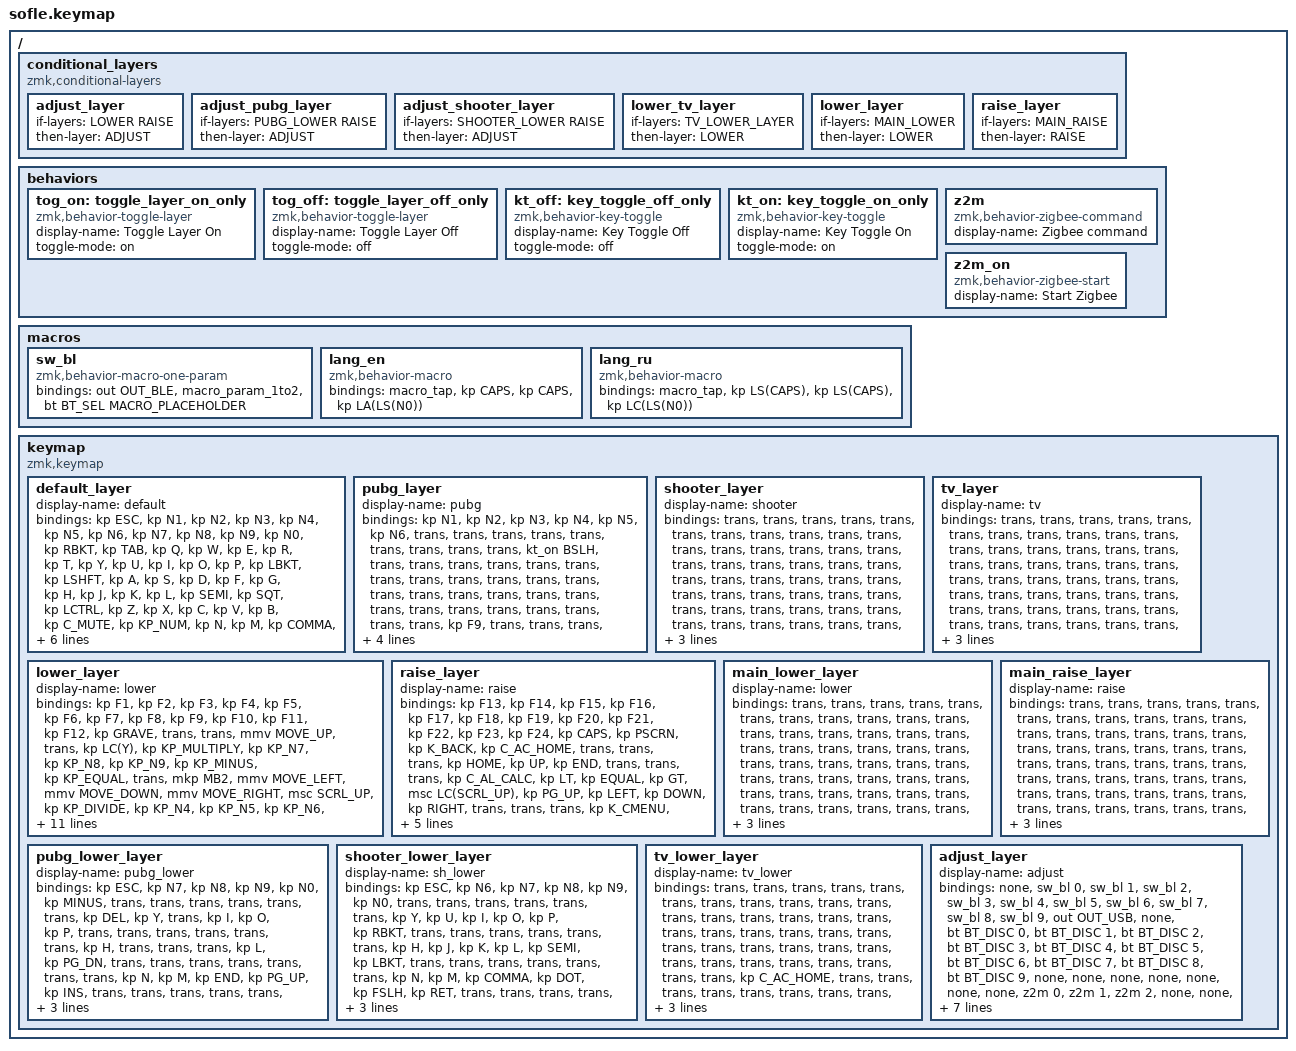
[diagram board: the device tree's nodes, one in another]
/*
 * Copyright (c) 2020 The ZMK Contributors
 *
 * SPDX-License-Identifier: MIT
 */

#include <behaviors.dtsi>
#include <dt-bindings/zmk/keys.h>
#include <dt-bindings/zmk/bt.h>
#include <dt-bindings/zmk/rgb.h>
#include <dt-bindings/zmk/ext_power.h>
#include <dt-bindings/zmk/outputs.h>
#include <dt-bindings/zmk/backlight.h>
#include <dt-bindings/zmk/language.h>
#include <dt-bindings/zmk/dynamic_macro.h>

#define ZMK_POINTING_DEFAULT_MOVE_VAL 1500
#define ZMK_POINTING_DEFAULT_SCRL_VAL 40    // default: 10

#include <dt-bindings/zmk/pointing.h>

#define BASE           0
#define PUBG           1
#define SHOOTER        2
#define TV_LAYER       3
#define LOWER          4
#define RAISE          5
#define MAIN_LOWER     6
#define MAIN_RAISE     7
#define PUBG_LOWER     8
#define SHOOTER_LOWER  9
#define TV_LOWER_LAYER 10
#define ADJUST         11

/ {
    conditional_layers {
        compatible = "zmk,conditional-layers";
        adjust_layer {
            if-layers = <LOWER RAISE>;
            then-layer = <ADJUST>;
        };
        adjust_pubg_layer {
            if-layers = <PUBG_LOWER RAISE>;
            then-layer = <ADJUST>;
        };
        adjust_shooter_layer {
            if-layers = <SHOOTER_LOWER RAISE>;
            then-layer = <ADJUST>;
        };
        lower_tv_layer {
            if-layers = <TV_LOWER_LAYER>;
            then-layer = <LOWER>;
        };
        lower_layer {
            if-layers = <MAIN_LOWER>;
            then-layer = <LOWER>;
        };
        raise_layer {
            if-layers = <MAIN_RAISE>;
            then-layer = <RAISE>;
        };
    };

    behaviors {
        tog_on: toggle_layer_on_only {
            compatible = "zmk,behavior-toggle-layer";
            #binding-cells = <1>;
            display-name = "Toggle Layer On";
            toggle-mode = "on";
        };
        tog_off: toggle_layer_off_only {
            compatible = "zmk,behavior-toggle-layer";
            #binding-cells = <1>;
            display-name = "Toggle Layer Off";
            toggle-mode = "off";
        };
        kt_off: key_toggle_off_only {
            compatible = "zmk,behavior-key-toggle";
            #binding-cells = <1>;
            display-name = "Key Toggle Off";
            toggle-mode = "off";
        };
        kt_on: key_toggle_on_only {
            compatible = "zmk,behavior-key-toggle";
            #binding-cells = <1>;
            display-name = "Key Toggle On";
            toggle-mode = "on";
        };
        z2m: z2m {
            compatible = "zmk,behavior-zigbee-command";
            #binding-cells = <1>;
            display-name = "Zigbee command";
        };
        z2m_on: z2m_on {
            compatible = "zmk,behavior-zigbee-start";
            #binding-cells = <0>;
            display-name = "Start Zigbee";
        };
    };

    macros {
        sw_bl: sw_bl {
            compatible = "zmk,behavior-macro-one-param";
            #binding-cells = <1>;
            bindings
                = <&out OUT_BLE>
                , <&macro_param_1to2>
                , <&bt BT_SEL MACRO_PLACEHOLDER>
                ;
        };
        lang_en: lang_en {
            compatible = "zmk,behavior-macro";
            #binding-cells = <0>;
            bindings
                = <&macro_tap &kp CAPS &kp CAPS &kp LA(LS(N0))>
                ;
        };
        lang_ru: lang_ru {
            compatible = "zmk,behavior-macro";
            #binding-cells = <0>;
            bindings
                = <&macro_tap &kp LS(CAPS) &kp LS(CAPS) &kp LC(LS(N0))>
                ;
        };
    };

    keymap {
        compatible = "zmk,keymap";

        default_layer {
            display-name = "default";
            bindings = <
&kp ESC   &kp N1 &kp N2   &kp N3   &kp N4         &kp N5                                             &kp N6   &kp N7         &kp N8    &kp N9  &kp N0   &kp RBKT
&kp TAB   &kp Q  &kp W    &kp E    &kp R          &kp T                                              &kp Y    &kp U          &kp I     &kp O   &kp P    &kp LBKT
&kp LSHFT &kp A  &kp S    &kp D    &kp F          &kp G                                              &kp H    &kp J          &kp K     &kp L   &kp SEMI &kp SQT
&kp LCTRL &kp Z  &kp X    &kp C    &kp V          &kp B     &kp C_MUTE                    &kp KP_NUM &kp N    &kp M          &kp COMMA &kp DOT &kp FSLH &kp RCTRL
                 &kp LGUI &kp LALT &mo MAIN_LOWER &kp SPACE &kp DEL                       &kp RET    &kp BSPC &mo MAIN_RAISE &kp RALT  &kp INS
            >;

            sensor-bindings = <&inc_dec_kp C_VOLUME_UP C_VOLUME_DOWN &inc_dec_kp K_VOLUME_DOWN K_VOLUME_UP>;
        };

        pubg_layer {
            display-name = "pubg";
            bindings = <
&kp N1 &kp N2 &kp N3 &kp N4       &kp N5      &kp N6                                             &trans &trans &trans &trans &trans &trans
&trans &trans &trans &kt_on BSLH  &trans      &trans                                             &trans &trans &trans &trans &trans &trans
&trans &trans &trans &trans       &trans      &trans                                             &trans &trans &trans &trans &trans &trans
&trans &trans &trans &trans       &trans      &trans    &kp F9                            &trans &trans &trans &trans &trans &trans &trans
              &kp E  &kp KP_MINUS &kp KP_PLUS &kp SPACE &mo PUBG_LOWER                    &trans &trans &trans &trans &trans
            >;
        };

        shooter_layer {
            display-name = "shooter";
            bindings = <
&trans &trans &trans   &trans &trans            &trans                                  &trans &trans &trans &trans &trans &trans
&trans &trans &trans   &trans &trans            &trans                                  &trans &trans &trans &trans &trans &trans
&trans &trans &trans   &trans &trans            &trans                                  &trans &trans &trans &trans &trans &trans
&trans &trans &trans   &trans &trans            &trans &trans                    &trans &trans &trans &trans &trans &trans &trans
              &kp BSPC &trans &mo SHOOTER_LOWER &trans &trans                    &trans &trans &trans &trans &trans
            >;
        };

        tv_layer {
            display-name = "tv";
            bindings = <
&trans &trans &trans &trans &trans             &trans                                  &trans &trans &trans &trans &trans &trans
&trans &trans &trans &trans &trans             &trans                                  &trans &trans &trans &trans &trans &trans
&trans &trans &trans &trans &trans             &trans                                  &trans &trans &trans &trans &trans &trans
&trans &trans &trans &trans &trans             &trans &trans                    &trans &trans &trans &trans &trans &trans &trans
              &trans &trans &mo TV_LOWER_LAYER &trans &trans                    &trans &trans &trans &trans &trans
            >;
        };

        lower_layer {
            display-name = "lower";
            bindings = <
&kp F1    &kp F2   &kp F3                      &kp F4                      &kp F5          &kp F6                                                              &kp F7          &kp F8    &kp F9    &kp F10    &kp F11           &kp F12
&kp GRAVE &trans   &trans                      &mmv MOVE_UP                &trans          &kp LC(Y)                                                           &kp KP_MULTIPLY &kp KP_N7 &kp KP_N8 &kp KP_N9  &kp KP_MINUS      &kp KP_EQUAL
&trans    &mkp MB2 &mmv MOVE_LEFT              &mmv MOVE_DOWN              &mmv MOVE_RIGHT &msc SCRL_UP                                                        &kp KP_DIVIDE   &kp KP_N4 &kp KP_N5 &kp KP_N6  &kp KP_PLUS       &trans
&trans    &mkp MB1 &mkp MB4                    &mkp MB3                    &mkp MB5        &msc SCRL_DOWN &kp C_PLAY_PAUSE                    &kp K_PLAY_PAUSE &kp KP_N0       &kp KP_N1 &kp KP_N2 &kp KP_N3  &lang_kp DOT FSLH &trans
                   &lang_ch LANG_EN LC(LS(N1)) &lang_ch LANG_RU LC(LS(N0)) &trans          &kp BSPC       &kp RET                             &trans           &trans          &trans    &kp KP_N0 &kp KP_DOT
            >;

            sensor-bindings = <&inc_dec_kp C_NEXT C_PREVIOUS &inc_dec_kp K_PREVIOUS K_NEXT>;
        };

        raise_layer {
            display-name = "raise";
            bindings = <
&kp F13  &kp F14       &kp F15    &kp F16       &kp F17        &kp F18                                             &kp F19   &kp F20  &kp F21  &kp F22   &kp F23  &kp F24
&kp CAPS &kp PSCRN     &kp K_BACK &kp C_AC_HOME &trans         &trans                                              &trans    &kp HOME &kp UP   &kp END   &trans   &trans
&trans   &kp C_AL_CALC &kp LT     &kp EQUAL     &kp GT         &msc LC(SCRL_UP)                                    &kp PG_UP &kp LEFT &kp DOWN &kp RIGHT &trans   &trans
&trans   &kp K_CMENU   &trans     &kp MINUS     &kp UNDERSCORE &msc LC(SCRL_DOWN) &trans                    &trans &kp PG_DN &trans   &trans   &trans    &kp BSLH &trans
                       &trans     &trans        &trans         &trans             &trans                    &trans &trans    &trans   &trans   &trans
            >;
        };

        main_lower_layer {
            display-name = "lower";
            bindings = <
&trans &trans &trans &trans &trans &trans                                  &trans &trans &trans &trans &trans &trans
&trans &trans &trans &trans &trans &trans                                  &trans &trans &trans &trans &trans &trans
&trans &trans &trans &trans &trans &trans                                  &trans &trans &trans &trans &trans &trans
&trans &trans &trans &trans &trans &trans &trans                    &trans &trans &trans &trans &trans &trans &trans
              &trans &trans &trans &trans &trans                    &trans &trans &trans &trans &trans
            >;
        };

        main_raise_layer {
            display-name = "raise";
            bindings = <
&trans &trans &trans &trans &trans &trans                                  &trans &trans &trans &trans &trans &trans
&trans &trans &trans &trans &trans &trans                                  &trans &trans &trans &trans &trans &trans
&trans &trans &trans &trans &trans &trans                                  &trans &trans &trans &trans &trans &trans
&trans &trans &trans &trans &trans &trans &trans                    &trans &trans &trans &trans &trans &trans &trans
              &trans &trans &trans &trans &trans                    &trans &trans &trans &trans &trans
            >;
        };

        pubg_lower_layer {
            display-name = "pubg_lower";
            bindings = <
&kp ESC &kp N7 &kp N8   &kp N9          &kp N0        &kp MINUS                                  &trans &trans &trans &trans &trans &trans
&kp DEL &kp Y  &trans   &kp I           &kp O         &kp P                                      &trans &trans &trans &trans &trans &trans
&kp H   &trans &trans   &trans          &kp L         &kp PG_DN                                  &trans &trans &trans &trans &trans &trans
&trans  &kp N  &kp M    &kp END         &kp PG_UP     &kp INS   &trans                    &trans &trans &trans &trans &trans &trans &trans
               &kp LALT &kp KP_MULTIPLY &kp KP_DIVIDE &kp HOME  &none                     &trans &trans &trans &trans &trans
            >;
        };

        shooter_lower_layer {
            display-name = "sh_lower";
            bindings = <
&kp ESC &kp N6 &kp N7    &kp N8  &kp N9   &kp N0                                        &trans &trans &trans &trans &trans &trans
&kp Y   &kp U  &kp I     &kp O   &kp P    &kp RBKT                                      &trans &trans &trans &trans &trans &trans
&kp H   &kp J  &kp K     &kp L   &kp SEMI &kp LBKT                                      &trans &trans &trans &trans &trans &trans
&kp N   &kp M  &kp COMMA &kp DOT &kp FSLH &kp RET   &trans                       &trans &trans &trans &trans &trans &trans &trans
               &kp HOME  &kp END &trans   &kp PG_UP &kp PG_DN                    &trans &trans &trans &trans &trans
            >;
        };

        tv_lower_layer {
            display-name = "tv_lower";
            bindings = <
&trans &trans        &trans &trans &trans &trans                                  &trans &trans &trans &trans &trans &trans
&trans &trans        &trans &trans &trans &trans                                  &trans &trans &trans &trans &trans &trans
&trans &trans        &trans &trans &trans &trans                                  &trans &trans &trans &trans &trans &trans
&trans &kp C_AC_HOME &trans &trans &trans &trans &trans                    &trans &trans &trans &trans &trans &trans &trans
                     &trans &trans &trans &trans &trans                    &trans &trans &trans &trans &trans
            >;
        };

        adjust_layer {
            display-name = "adjust";
            bindings = <
&none    &sw_bl 0      &sw_bl 1      &sw_bl 2      &sw_bl 3                          &sw_bl 4                                                 &sw_bl 5      &sw_bl 6      &sw_bl 7      &sw_bl 8      &sw_bl 9      &out OUT_USB
&none    &bt BT_DISC 0 &bt BT_DISC 1 &bt BT_DISC 2 &bt BT_DISC 3                     &bt BT_DISC 4                                            &bt BT_DISC 5 &bt BT_DISC 6 &bt BT_DISC 7 &bt BT_DISC 8 &bt BT_DISC 9 &none
&none    &none         &none         &none         &none                             &none                                                    &z2m 0        &z2m 1        &z2m 2        &none         &none         &none
&to BASE &to PUBG      &to TV_LAYER  &to SHOOTER   &rgb_ug RGB_COLOR_HSB(240,100,40) &none         &none                          &z2m_on     &z2m 255      &none         &none         &none         &none         &bt BT_CLR
                       &none         &none         &none                             &sys_reset    &bootloader                    &bootloader &sys_reset    &none         &none         &none
            >;
        };
    };
};
